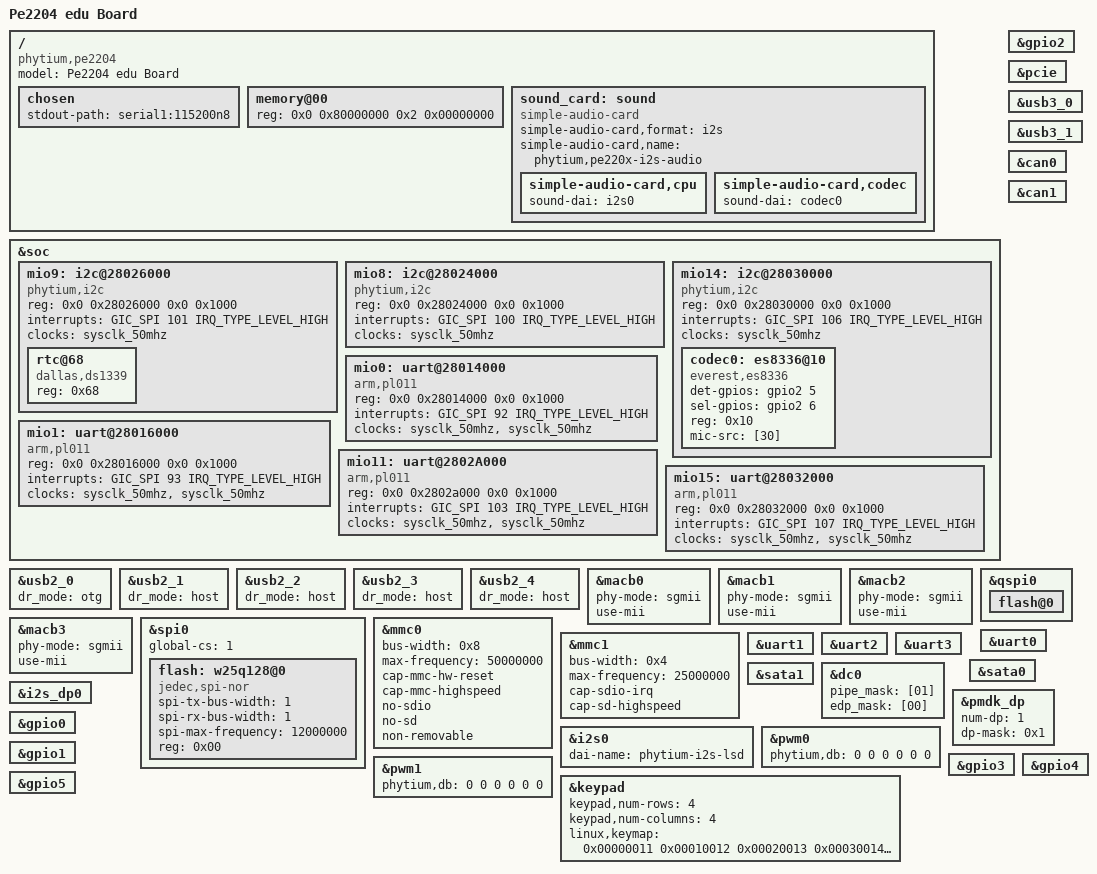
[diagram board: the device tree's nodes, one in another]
// SPDX-License-Identifier: GPL-2.0
/*
 * DTS file for Phytium Pe2204 edu board
 *
 * Copyright (c) 2022-2023 Phytium Technology Co., Ltd.
 *
 * Hongmin Qi <qihongmin@phytium.com.cn>
 *
 * This program is free software; you can redistribute it and/or
 * modify it under the terms of the GNU General Public License as
 * published by the Free Software Foundation; either version 2 of
 * the License, or (at your option) any later version.
 */

/dts-v1/;
/memreserve/ 0x80000000 0x10000;

#include "pe2204.dtsi"

/{
	model = "Pe2204 edu Board";
	compatible = "phytium,pe2204";

	chosen {
		stdout-path = "serial1:115200n8";
	};

	memory@00{
		device_type = "memory";
		reg = <0x0 0x80000000 0x2 0x00000000>;
	};

	sound_card: sound {
		compatible = "simple-audio-card";
		simple-audio-card,format = "i2s";
		simple-audio-card,name = "phytium,pe220x-i2s-audio";
		simple-audio-card,cpu {
			sound-dai = <&i2s0>;
		};
		simple-audio-card,codec {
			sound-dai = <&codec0>;
		};
	};
};

&soc {
	mio9: i2c@28026000 {
		compatible = "phytium,i2c";
		reg = <0x0 0x28026000 0x0 0x1000>;
		interrupts = <GIC_SPI 101 IRQ_TYPE_LEVEL_HIGH>;
		clocks = <&sysclk_50mhz>;
		#address-cells = <0x1>;
		#size-cells = <0x0>;
		status = "okay";

		rtc@68 {
			compatible = "dallas,ds1339";
			reg = <0x68>;
		};
	};

	mio8: i2c@28024000 {
		compatible = "phytium,i2c";
		reg = <0x0 0x28024000 0x0 0x1000>;
		interrupts = <GIC_SPI 100 IRQ_TYPE_LEVEL_HIGH>;
		clocks = <&sysclk_50mhz>;
		#address-cells = <0x1>;
		#size-cells = <0x0>;
		status = "okay";
	};

	mio14: i2c@28030000 {
		compatible = "phytium,i2c";
		reg = <0x0 0x28030000 0x0 0x1000>;
		interrupts = <GIC_SPI 106 IRQ_TYPE_LEVEL_HIGH>;
		clocks = <&sysclk_50mhz>;
		#address-cells = <0x1>;
		#size-cells = <0x0>;
		status = "okay";

		codec0:es8336@10 {
			det-gpios = <&gpio2 5 0>;
			sel-gpios = <&gpio2 6 0>;
			#sound-dai-cells = <0x0>;
			compatible = "everest,es8336";
			reg = <0x10>;
			mic-src = [30];
	   };
	};

	mio0: uart@28014000 {
		compatible = "arm,pl011", "arm,primecell";
		reg = <0x0 0x28014000 0x0 0x1000>;
		interrupts = <GIC_SPI 92 IRQ_TYPE_LEVEL_HIGH>;
		clocks = <&sysclk_50mhz &sysclk_50mhz>;
		clock-names = "uartclk", "apb_pclk";
		status = "okay";
	};

	mio1: uart@28016000 {
		compatible = "arm,pl011", "arm,primecell";
		reg = <0x0 0x28016000 0x0 0x1000>;
		interrupts = <GIC_SPI 93 IRQ_TYPE_LEVEL_HIGH>;
		clocks = <&sysclk_50mhz &sysclk_50mhz>;
		clock-names = "uartclk", "apb_pclk";
		status = "okay";
	};

	mio11: uart@2802A000 {
		compatible = "arm,pl011", "arm,primecell";
		reg = <0x0 0x2802a000 0x0 0x1000>;
		interrupts = <GIC_SPI 103 IRQ_TYPE_LEVEL_HIGH>;
		clocks = <&sysclk_50mhz &sysclk_50mhz>;
		clock-names = "uartclk", "apb_pclk";
		status = "okay";
	};

	mio15: uart@28032000 {
		compatible = "arm,pl011", "arm,primecell";
		reg = <0x0 0x28032000 0x0 0x1000>;
		interrupts = <GIC_SPI 107 IRQ_TYPE_LEVEL_HIGH>;
		clocks = <&sysclk_50mhz &sysclk_50mhz>;
		clock-names = "uartclk", "apb_pclk";
		status = "okay";
	};
};

&gpio2 {
	status = "okay";
};

&pcie {
	status = "okay";
};

&usb3_0 {
	status = "okay";
};

&usb3_1 {
	//status = "okay";
};

&usb2_0 {
	dr_mode = "otg";
	status = "okay";
};

&usb2_1 {
	dr_mode = "host";
	//status = "okay";
};

&usb2_2 {
	dr_mode = "host";
	//status = "okay";
};

&usb2_3 {
	dr_mode = "host";
	status = "okay";
};

&usb2_4 {
	dr_mode = "host";
	//status = "okay";
};

&macb0 {
	phy-mode = "sgmii";
	use-mii;
	//status = "okay";
};

&macb1 {
	phy-mode = "sgmii";
	use-mii;
	//status = "okay";
};

&macb2 {
	phy-mode = "sgmii";
	use-mii;
	//status = "okay";
};

&macb3 {
	phy-mode = "sgmii";
	use-mii;
	status = "okay";
};

&can0 {
	status = "okay";
};

&can1 {
	status = "okay";
};

&qspi0 {
	status = "okay";

	flash@0 {
		status = "okay";
	};
};

&spi0 {
	global-cs = <1>;
	status = "okay";

	flash: w25q128@0 {
		compatible = "jedec,spi-nor";
		spi-tx-bus-width = <1>;
		spi-rx-bus-width = <1>;
		spi-max-frequency = <12000000>;
		reg = <0x00>;
		status = "okay";
	};
};

&mmc0 {
	bus-width = <0x8>;
	max-frequency = <50000000>;
	cap-mmc-hw-reset;
	cap-mmc-highspeed;
	no-sdio;
	no-sd;
	non-removable;
	status = "okay";
};

&mmc1 {
	bus-width = <0x4>;
	max-frequency = <25000000>;
	cap-sdio-irq;
	cap-sd-highspeed;
	status = "okay";
};

&uart0 {
	status = "okay";
};

&uart1 {
	status = "okay";
};

&uart2 {
	status = "okay";
};

&uart3 {
	status = "okay";
};

&sata0 {
	//status = "okay";
};

&sata1 {
	status = "okay";
};

&dc0 {
	status = "okay";
	pipe_mask = [01];
	edp_mask = [00];
};

&i2s0 {
	#sound-dai-cells = <0>;
	dai-name = "phytium-i2s-lsd";
	status = "okay";
};

&i2s_dp0 {
	status = "okay";
};

&pmdk_dp {
	num-dp = <1>;
	dp-mask = /bits/ 8 <0x1>;
	status = "okay";
};

&pwm0 {
	phytium,db = <0 0 0 0 0 0>;
	status = "okay";
};

&pwm1 {
	phytium,db = <0 0 0 0 0 0>;
	status = "okay";
};


&gpio0 {
	status = "okay";
};

&gpio1 {
	status = "okay";
};

&gpio2 {
	status = "okay";
};

&gpio3 {
	status = "okay";
};

&gpio4 {
	status = "okay";
};

&gpio5 {
	status = "okay";
};

&keypad {
	keypad,num-rows = <4>;
	keypad,num-columns = <4>;
	linux,keymap = <0x00000011
					0x00010012
					0x00020013
					0x00030014
					0x01000021 /*KEY_21*/
					0x01010022 /*KEY_22*/
					0x01020023 /*KEY_23*/
					0x01030024 /*KEY_24*/
					0x02000031 /*KEY_31*/
					0x02010032 /*KEY_32*/
					0x02020033 /*KEY_33*/
					0x02030034 /*KEY_34*/
					0x03000041 /*KEY_41*/
					0x03010042 /*KEY_42*/
					0x03020043 /*KEY_43*/
					0x03030044 /*KEY_44*/>;
	status = "okay";
};
